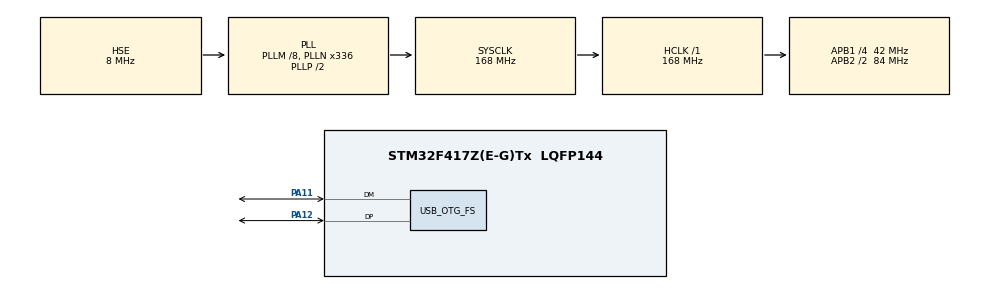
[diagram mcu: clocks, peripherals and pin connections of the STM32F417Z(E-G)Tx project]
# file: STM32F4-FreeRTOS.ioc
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FREERTOS.MEMORY_ALLOCATION=0
FREERTOS.Tasks01=defaultTask,0,4096,StartDefaultTask,Default,NULL,Dynamic,NULL,NULL
FREERTOS.configCHECK_FOR_STACK_OVERFLOW=2
FREERTOS.configENABLE_BACKWARD_COMPATIBILITY=0
FREERTOS.configGENERATE_RUN_TIME_STATS=1
FREERTOS.configTOTAL_HEAP_SIZE=65536
FREERTOS.configUSE_COUNTING_SEMAPHORES=1
FREERTOS.configUSE_MALLOC_FAILED_HOOK=1
FREERTOS.configUSE_STATS_FORMATTING_FUNCTIONS=1
FREERTOS.configUSE_TICK_HOOK=1
FREERTOS.configUSE_TRACE_FACILITY=1
Mcu.Family=STM32F4
Mcu.Name=STM32F417Z(E-G)Tx
Mcu.Package=LQFP144
NVIC.HASH_RNG_IRQn=true\:5\:0\:false\:false\:true\:true\:true
NVIC.OTG_FS_IRQn=true\:5\:0\:false\:false\:true\:true\:false
NVIC.PriorityGroup=NVIC_PRIORITYGROUP_4
PA11.Mode=Device_Only
PA11.Signal=USB_OTG_FS_DM
PA12.Mode=Device_Only
PA12.Signal=USB_OTG_FS_DP
PA13.Mode=Serial_Wire
PA13.Signal=SYS_JTMS-SWDIO
PA14.Mode=Serial_Wire
PA14.Signal=SYS_JTCK-SWCLK
PH0-OSC_IN.Mode=HSE-External-Oscillator
PH0-OSC_IN.Signal=RCC_OSC_IN
PH1-OSC_OUT.Mode=HSE-External-Oscillator
PH1-OSC_OUT.Signal=RCC_OSC_OUT
ProjectManager.HeapSize=0x200
ProjectManager.StackSize=0x400
ProjectManager.TargetToolchain=TrueSTUDIO
RCC.48MHZClocksFreq_Value=48000000
RCC.AHBFreq_Value=168000000
RCC.APB1CLKDivider=RCC_HCLK_DIV4
RCC.APB1Freq_Value=42000000
RCC.APB1TimFreq_Value=84000000
RCC.APB2CLKDivider=RCC_HCLK_DIV2
RCC.APB2Freq_Value=84000000
RCC.APB2TimFreq_Value=168000000
RCC.CortexFreq_Value=168000000
RCC.HCLKFreq_Value=168000000
RCC.HSE_VALUE=8000000
RCC.HSI_VALUE=16000000
RCC.LSE_VALUE=32768
RCC.PLLM=8
RCC.PLLN=336
RCC.PLLQ=7
RCC.SYSCLKFreq_VALUE=168000000
RCC.SYSCLKSource=RCC_SYSCLKSOURCE_PLLCLK
RCC.VCOOutputFreq_Value=336000000
USB_DEVICE.CLASS_NAME_FS=CDC
USB_DEVICE.VirtualMode-CDC_FS=Cdc
USB_DEVICE.VirtualModeFS=Cdc_FS
USB_OTG_FS.VirtualMode=Device_Only
USB_OTG_FS.vbus_sensing_enable=DISABLE
VP_CRC_VS_CRC.Mode=CRC_Activate
VP_FREERTOS_VS_ENABLE.Mode=Enabled
VP_RNG_VS_RNG.Mode=RNG_Activate
VP_USB_DEVICE_VS_USB_DEVICE_CDC_FS.Mode=CDC_FS
board=STM32F4-FreeRTOS

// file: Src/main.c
/**
  ******************************************************************************
  * @file           : main.c
  * @brief          : Main program body
  ******************************************************************************
  * This notice applies to any and all portions of this file
  * that are not between comment pairs USER CODE BEGIN and
  * USER CODE END. Other portions of this file, whether
  * inserted by the user or by software development tools
  * are owned by their respective copyright owners.
  *
  * Copyright (c) 2018 STMicroelectronics International N.V.
  * All rights reserved.
  *
  * Redistribution and use in source and binary forms, with or without
  * modification, are permitted, provided that the following conditions are met:
  *
  * 1. Redistribution of source code must retain the above copyright notice,
  *    this list of conditions and the following disclaimer.
  * 2. Redistributions in binary form must reproduce the above copyright notice,
  *    this list of conditions and the following disclaimer in the documentation
  *    and/or other materials provided with the distribution.
  * 3. Neither the name of STMicroelectronics nor the names of other
  *    contributors to this software may be used to endorse or promote products
  *    derived from this software without specific written permission.
  * 4. This software, including modifications and/or derivative works of this
  *    software, must execute solely and exclusively on microcontroller or
  *    microprocessor devices manufactured by or for STMicroelectronics.
  * 5. Redistribution and use of this software other than as permitted under
  *    this license is void and will automatically terminate your rights under
  *    this license.
  *
  * THIS SOFTWARE IS PROVIDED BY STMICROELECTRONICS AND CONTRIBUTORS "AS IS"
  * AND ANY EXPRESS, IMPLIED OR STATUTORY WARRANTIES, INCLUDING, BUT NOT
  * LIMITED TO, THE IMPLIED WARRANTIES OF MERCHANTABILITY, FITNESS FOR A
  * PARTICULAR PURPOSE AND NON-INFRINGEMENT OF THIRD PARTY INTELLECTUAL PROPERTY
  * RIGHTS ARE DISCLAIMED TO THE FULLEST EXTENT PERMITTED BY LAW. IN NO EVENT
  * SHALL STMICROELECTRONICS OR CONTRIBUTORS BE LIABLE FOR ANY DIRECT, INDIRECT,
  * INCIDENTAL, SPECIAL, EXEMPLARY, OR CONSEQUENTIAL DAMAGES (INCLUDING, BUT NOT
  * LIMITED TO, PROCUREMENT OF SUBSTITUTE GOODS OR SERVICES; LOSS OF USE, DATA,
  * OR PROFITS; OR BUSINESS INTERRUPTION) HOWEVER CAUSED AND ON ANY THEORY OF
  * LIABILITY, WHETHER IN CONTRACT, STRICT LIABILITY, OR TORT (INCLUDING
  * NEGLIGENCE OR OTHERWISE) ARISING IN ANY WAY OUT OF THE USE OF THIS SOFTWARE,
  * EVEN IF ADVISED OF THE POSSIBILITY OF SUCH DAMAGE.
  *
  ******************************************************************************
  */
#include "main.h"
#include "stm32f4xx_hal.h"
#include "cmsis_os.h"
#include "usb_device.h"

CRC_HandleTypeDef hcrc;

RNG_HandleTypeDef hrng;

osThreadId defaultTaskHandle;

/* USER CODE BEGIN PV */
/* Private variables ---------------------------------------------------------*/

/* USER CODE END PV */

void SystemClock_Config(void);
static void MX_GPIO_Init(void);
static void MX_CRC_Init(void);
static void MX_RNG_Init(void);
void StartDefaultTask(void const * argument);

/* USER CODE BEGIN PFP */
/* Private function prototypes -----------------------------------------------*/

/* USER CODE END PFP */

int main(void)
{

  /* MCU Configuration----------------------------------------------------------*/

  /* Reset of all peripherals, Initializes the Flash interface and the Systick. */
  HAL_Init();

  /* Configure the system clock */
  SystemClock_Config();

  /* Initialize all configured peripherals */
  MX_GPIO_Init();
  MX_CRC_Init();
  MX_RNG_Init();

  /* Create the thread(s) */
  /* definition and creation of defaultTask */
  osThreadDef(defaultTask, StartDefaultTask, osPriorityNormal, 0, 4096);
  defaultTaskHandle = osThreadCreate(osThread(defaultTask), NULL);

  /* Start scheduler */
  osKernelStart();

  /* We should never get here as control is now taken by the scheduler */

  /* Infinite loop */
  while (1)
  {

  }

}

void SystemClock_Config(void)
{

  RCC_OscInitTypeDef RCC_OscInitStruct;
  RCC_ClkInitTypeDef RCC_ClkInitStruct;

    /**Configure the main internal regulator output voltage
    */
  __HAL_RCC_PWR_CLK_ENABLE();

  __HAL_PWR_VOLTAGESCALING_CONFIG(PWR_REGULATOR_VOLTAGE_SCALE1);

    /**Initializes the CPU, AHB and APB busses clocks
    */
  RCC_OscInitStruct.OscillatorType = RCC_OSCILLATORTYPE_HSE;
  RCC_OscInitStruct.HSEState = RCC_HSE_ON;
  RCC_OscInitStruct.PLL.PLLState = RCC_PLL_ON;
  RCC_OscInitStruct.PLL.PLLSource = RCC_PLLSOURCE_HSE;
  RCC_OscInitStruct.PLL.PLLM = 8;
  RCC_OscInitStruct.PLL.PLLN = 336;
  RCC_OscInitStruct.PLL.PLLP = RCC_PLLP_DIV2;
  RCC_OscInitStruct.PLL.PLLQ = 7;
  if (HAL_RCC_OscConfig(&RCC_OscInitStruct) != HAL_OK)
  {
    _Error_Handler(__FILE__, __LINE__);
  }

    /**Initializes the CPU, AHB and APB busses clocks
    */
  RCC_ClkInitStruct.ClockType = RCC_CLOCKTYPE_HCLK|RCC_CLOCKTYPE_SYSCLK
                              |RCC_CLOCKTYPE_PCLK1|RCC_CLOCKTYPE_PCLK2;
  RCC_ClkInitStruct.SYSCLKSource = RCC_SYSCLKSOURCE_PLLCLK;
  RCC_ClkInitStruct.AHBCLKDivider = RCC_SYSCLK_DIV1;
  RCC_ClkInitStruct.APB1CLKDivider = RCC_HCLK_DIV4;
  RCC_ClkInitStruct.APB2CLKDivider = RCC_HCLK_DIV2;

  if (HAL_RCC_ClockConfig(&RCC_ClkInitStruct, FLASH_LATENCY_5) != HAL_OK)
  {
    _Error_Handler(__FILE__, __LINE__);
  }

    /**Configure the Systick interrupt time
    */
  HAL_SYSTICK_Config(HAL_RCC_GetHCLKFreq()/1000);

    /**Configure the Systick
    */
  HAL_SYSTICK_CLKSourceConfig(SYSTICK_CLKSOURCE_HCLK);

  /* SysTick_IRQn interrupt configuration */
  HAL_NVIC_SetPriority(SysTick_IRQn, 15, 0);
}

/* CRC init function */
static void MX_CRC_Init(void)
{

  hcrc.Instance = CRC;
  if (HAL_CRC_Init(&hcrc) != HAL_OK)
  {
    _Error_Handler(__FILE__, __LINE__);
  }

}

/* RNG init function */
static void MX_RNG_Init(void)
{

  hrng.Instance = RNG;
  if (HAL_RNG_Init(&hrng) != HAL_OK)
  {
    _Error_Handler(__FILE__, __LINE__);
  }

}

/** Configure pins as
        * Analog
        * Input
        * Output
        * EVENT_OUT
        * EXTI
*/
static void MX_GPIO_Init(void)
{

  /* GPIO Ports Clock Enable */
  __HAL_RCC_GPIOH_CLK_ENABLE();
  __HAL_RCC_GPIOA_CLK_ENABLE();

}

/* StartDefaultTask function */
void StartDefaultTask(void const * argument)
{
  /* init code for USB_DEVICE */
  MX_USB_DEVICE_Init();

  /* USER CODE BEGIN 5 */

  openThreadStart(0,0);
  /* Infinite loop */
  for(;;)
  {
    osDelay(1);
  }
  /* USER CODE END 5 */
}

void _Error_Handler(char *file, int line)
{
  while(1)
  {
  }
}

/************************ (C) COPYRIGHT STMicroelectronics *****END OF FILE****/

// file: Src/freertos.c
/**
  ******************************************************************************
  * File Name          : freertos.c
  * Description        : Code for freertos applications
  ******************************************************************************
  * This notice applies to any and all portions of this file
  * that are not between comment pairs USER CODE BEGIN and
  * USER CODE END. Other portions of this file, whether
  * inserted by the user or by software development tools
  * are owned by their respective copyright owners.
  *
  * Copyright (c) 2018 STMicroelectronics International N.V.
  * All rights reserved.
  *
  * Redistribution and use in source and binary forms, with or without
  * modification, are permitted, provided that the following conditions are met:
  *
  * 1. Redistribution of source code must retain the above copyright notice,
  *    this list of conditions and the following disclaimer.
  * 2. Redistributions in binary form must reproduce the above copyright notice,
  *    this list of conditions and the following disclaimer in the documentation
  *    and/or other materials provided with the distribution.
  * 3. Neither the name of STMicroelectronics nor the names of other
  *    contributors to this software may be used to endorse or promote products
  *    derived from this software without specific written permission.
  * 4. This software, including modifications and/or derivative works of this
  *    software, must execute solely and exclusively on microcontroller or
  *    microprocessor devices manufactured by or for STMicroelectronics.
  * 5. Redistribution and use of this software other than as permitted under
  *    this license is void and will automatically terminate your rights under
  *    this license.
  *
  * THIS SOFTWARE IS PROVIDED BY STMICROELECTRONICS AND CONTRIBUTORS "AS IS"
  * AND ANY EXPRESS, IMPLIED OR STATUTORY WARRANTIES, INCLUDING, BUT NOT
  * LIMITED TO, THE IMPLIED WARRANTIES OF MERCHANTABILITY, FITNESS FOR A
  * PARTICULAR PURPOSE AND NON-INFRINGEMENT OF THIRD PARTY INTELLECTUAL PROPERTY
  * RIGHTS ARE DISCLAIMED TO THE FULLEST EXTENT PERMITTED BY LAW. IN NO EVENT
  * SHALL STMICROELECTRONICS OR CONTRIBUTORS BE LIABLE FOR ANY DIRECT, INDIRECT,
  * INCIDENTAL, SPECIAL, EXEMPLARY, OR CONSEQUENTIAL DAMAGES (INCLUDING, BUT NOT
  * LIMITED TO, PROCUREMENT OF SUBSTITUTE GOODS OR SERVICES; LOSS OF USE, DATA,
  * OR PROFITS; OR BUSINESS INTERRUPTION) HOWEVER CAUSED AND ON ANY THEORY OF
  * LIABILITY, WHETHER IN CONTRACT, STRICT LIABILITY, OR TORT (INCLUDING
  * NEGLIGENCE OR OTHERWISE) ARISING IN ANY WAY OUT OF THE USE OF THIS SOFTWARE,
  * EVEN IF ADVISED OF THE POSSIBILITY OF SUCH DAMAGE.
  *
  ******************************************************************************
  */

#include "FreeRTOS.h"
#include "task.h"

/* Hook prototypes */
void configureTimerForRunTimeStats(void);
unsigned long getRunTimeCounterValue(void);
void vApplicationTickHook(void);
void vApplicationStackOverflowHook(TaskHandle_t xTask, signed char *pcTaskName);
void vApplicationMallocFailedHook(void);

/* USER CODE BEGIN 1 */
/* Functions needed when configGENERATE_RUN_TIME_STATS is on */
__weak void configureTimerForRunTimeStats(void)
{

}

__weak unsigned long getRunTimeCounterValue(void)
{
return 0;
}
/* USER CODE END 1 */

/* USER CODE BEGIN 3 */
__weak void vApplicationTickHook( void )
{
   /* This function will be called by each tick interrupt if
   configUSE_TICK_HOOK is set to 1 in FreeRTOSConfig.h. User code can be
   added here, but the tick hook is called from an interrupt context, so
   code must not attempt to block, and only the interrupt safe FreeRTOS API
   functions can be used (those that end in FromISR()). */
	alarmTick();
}
/* USER CODE END 3 */

/* USER CODE BEGIN 4 */
__weak void vApplicationStackOverflowHook(TaskHandle_t xTask, signed char *pcTaskName)
{
   /* Run time stack overflow checking is performed if
   configCHECK_FOR_STACK_OVERFLOW is defined to 1 or 2. This hook function is
   called if a stack overflow is detected. */
	while(1);
}
/* USER CODE END 4 */

/* USER CODE BEGIN 5 */
__weak void vApplicationMallocFailedHook(void)
{
   /* vApplicationMallocFailedHook() will only be called if
   configUSE_MALLOC_FAILED_HOOK is set to 1 in FreeRTOSConfig.h. It is a hook
   function that will get called if a call to pvPortMalloc() fails.
   pvPortMalloc() is called internally by the kernel whenever a task, queue,
   timer or semaphore is created. It is also called by various parts of the
   demo application. If heap_1.c or heap_2.c are used, then the size of the
   heap available to pvPortMalloc() is defined by configTOTAL_HEAP_SIZE in
   FreeRTOSConfig.h, and the xPortGetFreeHeapSize() API function can be used
   to query the size of free heap space that remains (although it does not
   provide information on how the remaining heap might be fragmented). */
	while(1);
}
/* USER CODE END 5 */

/************************ (C) COPYRIGHT STMicroelectronics *****END OF FILE****/
